AUTOSAR XML (schema 4-2-2)
package /ComponentTypes
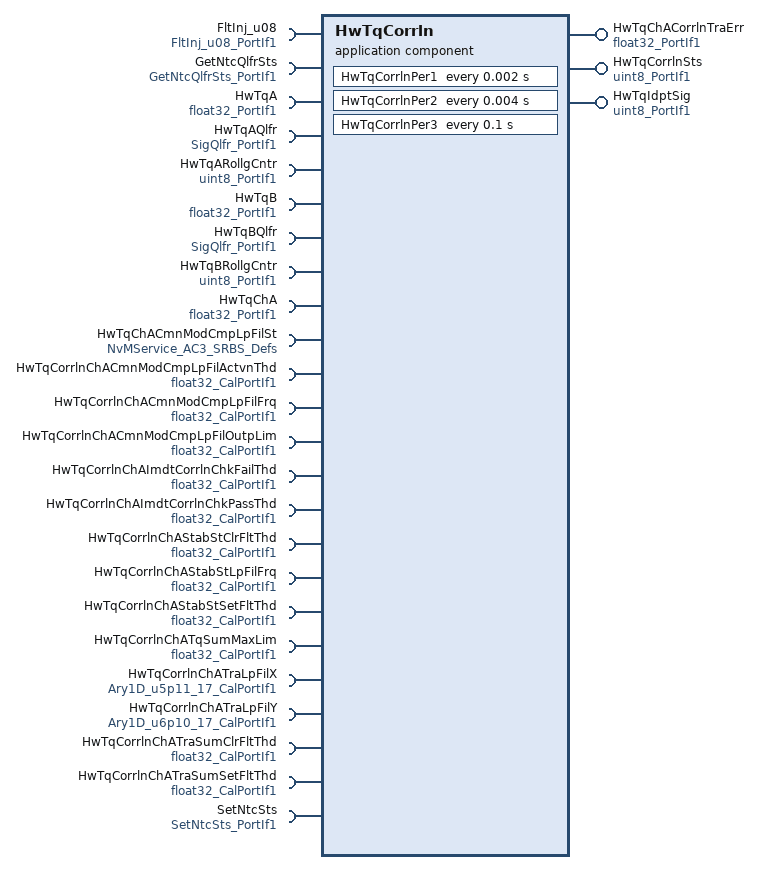
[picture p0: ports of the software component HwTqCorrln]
  application sw component type HwTqCorrln
    provide port HwTqChACorrlnTraErr: nonqueued-sender-com-spec{data-element=Val, init-value=0}, provided-interface=float32_PortIf1
    provide port HwTqCorrlnSts: nonqueued-sender-com-spec{data-element=Val, init-value=15}, provided-interface=uint8_PortIf1
    provide port HwTqIdptSig: nonqueued-sender-com-spec{data-element=Val, init-value=4}, provided-interface=uint8_PortIf1
    24 x require port:
      FltInj_u08: client-com-spec=Oper, required-interface=FltInj_u08_PortIf1
      GetNtcQlfrSts: client-com-spec=Oper, required-interface=GetNtcQlfrSts_PortIf1
      HwTqA: nonqueued-receiver-com-spec{data-element=Val, filter=data-filter-type=ALWAYS, init-value=0}, required-interface=float32_PortIf1
      HwTqAQlfr: nonqueued-receiver-com-spec{data-element=Val, filter=data-filter-type=ALWAYS, init-value=0}, required-interface=SigQlfr_PortIf1
      HwTqARollgCntr: nonqueued-receiver-com-spec{data-element=Val, filter=data-filter-type=ALWAYS, init-value=0}, required-interface=uint8_PortIf1
      HwTqB: nonqueued-receiver-com-spec{data-element=Val, filter=data-filter-type=ALWAYS, init-value=0}, required-interface=float32_PortIf1
      HwTqBQlfr: nonqueued-receiver-com-spec{data-element=Val, filter=data-filter-type=ALWAYS, init-value=0}, required-interface=SigQlfr_PortIf1
      HwTqBRollgCntr: nonqueued-receiver-com-spec{data-element=Val, filter=data-filter-type=ALWAYS, init-value=0}, required-interface=uint8_PortIf1
      HwTqChA: nonqueued-receiver-com-spec{data-element=Val, filter=data-filter-type=ALWAYS, init-value=0}, required-interface=float32_PortIf1
      HwTqChACmnModCmpLpFilSt: required-com-specs=[EraseBlock, GetErrorStatus, InvalidateNvBlock, ReadBlock, RestoreBlockDefaults, SetRamBlockStatus, WriteBlock], required-interface=NvMService_AC3_SRBS_Defs
      HwTqCorrlnChACmnModCmpLpFilActvnThd: parameter-require-com-spec{init-value=0.2857143, parameter=Val}, required-interface=float32_CalPortIf1
      HwTqCorrlnChACmnModCmpLpFilFrq: parameter-require-com-spec{init-value=0.01989437, parameter=Val}, required-interface=float32_CalPortIf1
      HwTqCorrlnChACmnModCmpLpFilOutpLim: parameter-require-com-spec{init-value=0.5714, parameter=Val}, required-interface=float32_CalPortIf1
      HwTqCorrlnChAImdtCorrlnChkFailThd: parameter-require-com-spec{init-value=2.85, parameter=Val}, required-interface=float32_CalPortIf1
      HwTqCorrlnChAImdtCorrlnChkPassThd: parameter-require-com-spec{init-value=2, parameter=Val}, required-interface=float32_CalPortIf1
      HwTqCorrlnChAStabStClrFltThd: parameter-require-com-spec{init-value=2.515, parameter=Val}, required-interface=float32_CalPortIf1
      HwTqCorrlnChAStabStLpFilFrq: parameter-require-com-spec{init-value=0.01989437, parameter=Val}, required-interface=float32_CalPortIf1
      HwTqCorrlnChAStabStSetFltThd: parameter-require-com-spec{init-value=2.85, parameter=Val}, required-interface=float32_CalPortIf1
      HwTqCorrlnChATqSumMaxLim: parameter-require-com-spec{init-value=20, parameter=Val}, required-interface=float32_CalPortIf1
      HwTqCorrlnChATraLpFilX: parameter-require-com-spec{init-value=[0, 1783, 3560, 5342, 7125, 8902, 10685, 12467, 14245, 16027, 17810, 19587, 21370, 23152, 24935, 26712, 28495], parameter=Ary1D}, required-interface=Ary1D_u5p11_17_CalPortIf1
      HwTqCorrlnChATraLpFilY: parameter-require-com-spec{init-value=[34873, 34873, 34873, 34873, 19910, 12411, 9199, 7350, 6137, 5272, 4623, 4119, 3714, 3382, 3104, 2870, 2668], parameter=Ary1D}, required-interface=Ary1D_u6p10_17_CalPortIf1
      HwTqCorrlnChATraSumClrFltThd: parameter-require-com-spec{init-value=1.425, parameter=Val}, required-interface=float32_CalPortIf1
      HwTqCorrlnChATraSumSetFltThd: parameter-require-com-spec{init-value=2.85, parameter=Val}, required-interface=float32_CalPortIf1
      SetNtcSts: client-com-spec=Oper, required-interface=SetNtcSts_PortIf1
    behavior HwTqCorrln_InternalBehavior
      ar-typed-per-instance-memorys:
        9 x data, all with sw-calibration-access=READ-ONLY:
          HwTqARollgCntrPrev: type=uint8
          HwTqAStallCntrPrev: type=uint8
          HwTqBRollgCntrPrev: type=uint8
          HwTqBStallCntrPrev: type=uint8
          HwTqChACmnModCmpLpFil: type=FilLpRec1
          HwTqChACmnModCmpLpFilSt: type=float32
          HwTqChAImdtCorrlnChk: type=boolean
          HwTqChAStabStLpFil: type=FilLpRec1
          HwTqChATraLpFil: type=FilLpRec1
      init event HwTqCorrln_InitEvent: start-on-event=HwTqCorrlnInit1
      timing event TMT_HwTqCorrlnPer1: start-on-event=HwTqCorrlnPer1, period=0.002
      timing event TMT_HwTqCorrlnPer2: start-on-event=HwTqCorrlnPer2, period=0.004
      timing event TMT_HwTqCorrlnPer3: start-on-event=HwTqCorrlnPer3, period=0.1
      explicit-inter-runnable-variables:
        data HwTqChAAvl: type=boolean, init-value=1
        data HwTqChATqSumLim: type=float32, init-value=0
      4 x runnable:
        HwTqCorrlnInit1
        HwTqCorrlnPer1
          data-receive-point-by-arguments:
            6 x access:
              REC_HwTqA_Val: accessed-variable=HwTqA.Val
              REC_HwTqAQlfr_Val: accessed-variable=HwTqAQlfr.Val
              REC_HwTqARollgCntr_Val: accessed-variable=HwTqARollgCntr.Val
              REC_HwTqB_Val: accessed-variable=HwTqB.Val
              REC_HwTqBQlfr_Val: accessed-variable=HwTqBQlfr.Val
              REC_HwTqBRollgCntr_Val: accessed-variable=HwTqBRollgCntr.Val
          data-send-points:
            access SEND_HwTqCorrlnSts_Val: accessed-variable=HwTqCorrlnSts.Val
          sync call SC_GetNtcQlfrSts_Oper: operation=GetNtcQlfrSts.Oper, timeout=0
          written-local-variables:
            access WRITE_HwTqChAAvl: accessed-variable=HwTqChAAvl
        HwTqCorrlnPer2
          data-receive-point-by-arguments:
            access REC_HwTqA_Val: accessed-variable=HwTqA.Val
            access REC_HwTqB_Val: accessed-variable=HwTqB.Val
          data-send-points:
            access SEND_HwTqChACorrlnTraErr_Val: accessed-variable=HwTqChACorrlnTraErr.Val
            access SEND_HwTqIdptSig_Val: accessed-variable=HwTqIdptSig.Val
          read-local-variables:
            access READ_HwTqChAAvl: accessed-variable=HwTqChAAvl
          sync call SC_FltInj_u08_Oper: operation=FltInj_u08.Oper, timeout=0
          sync call SC_GetNtcQlfrSts_Oper: operation=GetNtcQlfrSts.Oper, timeout=0
          sync call SC_SetNtcSts_Oper: operation=SetNtcSts.Oper, timeout=0
          written-local-variables:
            access WRITE_HwTqChATqSumLim: accessed-variable=HwTqChATqSumLim
        HwTqCorrlnPer3
          data-receive-point-by-arguments:
            access REC_HwTqChA_Val: accessed-variable=HwTqChA.Val
          read-local-variables:
            access READ_HwTqChATqSumLim: accessed-variable=HwTqChATqSumLim
          sync call SC_HwTqChACmnModCmpLpFilSt_SetRamBlockStatus: operation=HwTqChACmnModCmpLpFilSt.SetRamBlockStatus, timeout=0
      swc service dependency NvmHwTqChACmnModCmpLpFilSt: assigned-ports=role-based-port-assignment={port-prototype=HwTqChACmnModCmpLpFilSt, role=NvMService_AC3_SRBS_Defs}
        assigned-datas:
          role=ramBlock, used-data-element=HwTqChACmnModCmpLpFilSt
          role=defaultValue, used-parameter-element=HwTqChACmnModCmpLpFilStDft
        service-needs:
          nv block needs NvmHwTqChACmnModCmpLpFilSt: n-data-sets=0, ram-block-status-control=API, readonly=false, reliability=ERROR-DETECTION, resistant-to-changed-sw=true, restore-at-start=true, store-at-shutdown=true, write-only-once=false, writing-frequency=0, writing-priority=LOW
      shared-parameters:
        parameter data prototype HwTqChACmnModCmpLpFilStDft: sw-calibration-access=READ-WRITE, type=float32, init-value=0
  swc implementation HwTqCorrln_Implementation: behavior=HwTqCorrln_InternalBehavior
    code-descriptors:
      code Default: artifact-descriptors=autosar-engineering-object={short-label=Default, category=SWSRC}
